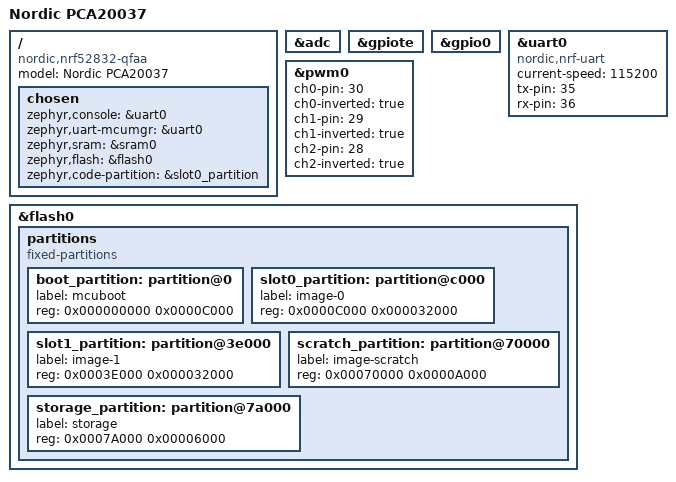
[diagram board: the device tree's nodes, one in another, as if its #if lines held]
/*
 * Copyright (c) 2019 Nordic Semiconductor ASA
 *
 * SPDX-License-Identifier: LicenseRef-BSD-5-Clause-Nordic
 */

/dts-v1/;
#include <nordic/nrf52832_qfaa.dtsi>

/ {
	model = "Nordic PCA20037";
	compatible = "nordic,nrf52832-qfaa",
		     "nordic,nrf52832";

	chosen {
		zephyr,console = &uart0;
#ifdef CONFIG_MCUMGR_SMP_UART
		zephyr,uart-mcumgr = &uart0;
#endif
		zephyr,sram = &sram0;
		zephyr,flash = &flash0;
		zephyr,code-partition = &slot0_partition;
	};
};

&adc {
	status ="ok";
};

&gpiote {
	status ="ok";
};

&gpio0 {
	status ="ok";
};

&uart0 {
	status = "ok";
	compatible = "nordic,nrf-uart";
	current-speed = <115200>;
	tx-pin = <35>;
	rx-pin = <36>;
};

&pwm0 {
	status = "ok";
	ch0-pin = <30>;
	ch0-inverted = "true";
	ch1-pin = <29>;
	ch1-inverted = "true";
	ch2-pin = <28>;
	ch2-inverted = "true";
};

&flash0 {
	/*
	 * For more information, see:
	 * http://docs.zephyrproject.org/devices/dts/flash_partitions.html
	 */
	partitions {
		compatible = "fixed-partitions";
		#address-cells = <1>;
		#size-cells = <1>;

		boot_partition: partition@0 {
			label = "mcuboot";
			reg = <0x000000000 0x0000C000>;
		};
		slot0_partition: partition@c000 {
			label = "image-0";
			reg = <0x0000C000 0x000032000>;
		};
		slot1_partition: partition@3e000 {
			label = "image-1";
			reg = <0x0003E000 0x000032000>;
		};
		scratch_partition: partition@70000 {
			label = "image-scratch";
			reg = <0x00070000 0x0000A000>;
		};
		storage_partition: partition@7a000 {
			label = "storage";
			reg = <0x0007A000 0x00006000>;
		};
	};
};
